# PCIe_SS1_RC_CFG_DBICS register map
Vendor: Texas Instruments
Peripheral module from a debugger description file (folder DRA75x_DRA74x).
Registers are 32-bit, access per field, reset 0x0 unless marked. A register's access mark holds for its fields unless they carry their own. Offsets are as the file gives them; lines under a group give offsets from that group; [hi:lo] are bit positions; {n}, {i} and the like mark numbered series; 'fields as' and 'values as' point back to an identical list; <NAME> marks a mode.

## PCIe_SS1_RC_CFG_DBICS
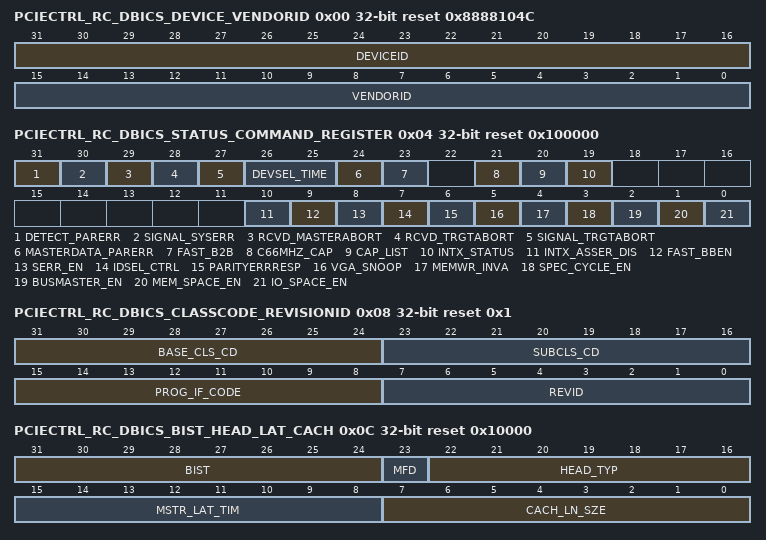
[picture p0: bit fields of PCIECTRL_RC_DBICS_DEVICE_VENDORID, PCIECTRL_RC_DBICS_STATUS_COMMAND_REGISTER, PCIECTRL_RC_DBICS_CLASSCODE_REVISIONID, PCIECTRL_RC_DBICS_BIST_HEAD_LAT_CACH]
0x00 PCIECTRL_RC_DBICS_DEVICE_VENDORID rw reset 0x8888104C — Device and Vendor ID
  [31:16] DEVICEID — Device ID (CS)
  [15:0] VENDORID — Vendor ID (CS)
0x04 PCIECTRL_RC_DBICS_STATUS_COMMAND_REGISTER reset 0x100000 — Status and Command registers
  [31] DETECT_PARERR rw — Detected Parity Error
  [30] SIGNAL_SYSERR rw — Signaled System Error
  [29] RCVD_MASTERABORT rw — Received Master Abort
  [28] RCVD_TRGTABORT rw — Received Target Abort
  [27] SIGNAL_TRGTABORT rw — Signaled Target Abort
  [26:25] DEVSEL_TIME ro — DevSel Timing, Harsdwired to 0 for PCIExpress
  [24] MASTERDATA_PARERR rw — Master Data Parity Error
  [23] FAST_B2B ro — Back to Back Capable, Harsdwired to 0 for PCIExpress
  [21] C66MHZ_CAP ro — 66MHz Capable, Harsdwired to 0 for PCIExpress
  [20] CAP_LIST ro — Capabilities List Hardwired to 1
  [19] INTX_STATUS ro
  [10] INTX_ASSER_DIS rw — INTx Assertion Disable
  [9] FAST_BBEN ro — Bit hardwired to 0 for PCIExpress
  [8] SERR_EN rw — SERR Enable
  [7] IDSEL_CTRL ro — Bit hardwired to 0 for PCIExpress
  [6] PARITYERRRESP rw — Parity Error Response
  [5] VGA_SNOOP ro — Not Applicable forPCI Express; Bit hardwired to 0 for PCIExpress
  [4] MEMWR_INVA ro — Not Applicable for PCI Express; Bit hardwired to 0 for PCIExpress
  [3] SPEC_CYCLE_EN ro — Not Applicable for PCI Express; Bit hardwired to 0 for PCIExpress
  [2] BUSMASTER_EN rw — Bus Master Enable (BME)
  [1] MEM_SPACE_EN rw — Memory Space Enable (MSE)
  [0] IO_SPACE_EN rw — IO Space Enable (ISE)
0x08 PCIECTRL_RC_DBICS_CLASSCODE_REVISIONID rw reset 0x1 — Class code and Revision ID
  [31:24] BASE_CLS_CD — Base Class Code (CS)
  [23:16] SUBCLS_CD — Sub Class Code (CS)
  [15:8] PROG_IF_CODE — Programming Interface Code (CS)
  [7:0] REVID — Revision ID (CS)
0x0C PCIECTRL_RC_DBICS_BIST_HEAD_LAT_CACH reset 0x10000 — BIST, Header Type, Latency Timer, Cache Line Size
  [31:24] BIST ro
  [23] MFD ro — MultiFunction Device
  [22:16] HEAD_TYP ro — Header Type
    0=TYPE0 (EP header (Type0)); 1=TYPE1 (RC header (Type1))
  [15:8] MSTR_LAT_TIM ro — Master Latency Timer, Not Applicable for PCIe hence hardwired to 0
  [7:0] CACH_LN_SZE rw — Cache Line Size, No impact on write, write is allowed only for legacy purpose
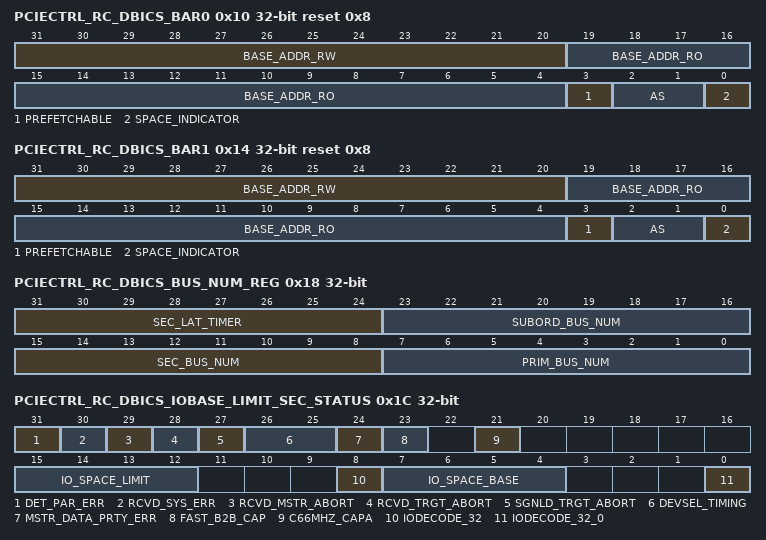
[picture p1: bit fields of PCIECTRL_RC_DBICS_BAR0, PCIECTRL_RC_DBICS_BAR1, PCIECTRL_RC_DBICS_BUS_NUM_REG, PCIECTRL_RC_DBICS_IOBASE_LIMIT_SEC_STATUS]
0x10 PCIECTRL_RC_DBICS_BAR0 reset 0x8 — Base Address Register 0 Bit #0 is also a WO BAR enable (CS2) BAR Mask is writable (CS2)
  [31:20] BASE_ADDR_RW rw — Base address bits (for a 64-bit BAR, upper base address bits are in BAR above). Unmasked MSBs, as set by BAR mask.NOTE: The RO and RW division between bits 19 and 20 is based on the assumption that BAR mask is 20 bits (1MB).
  [19:4] BASE_ADDR_RO ro — Base address bits (for a 64-bit BAR, upper base address bits are in BAR above). Masked LSBs, as set by BAR mask.NOTE: The RO and RW division between bits 19 and 20 is based on the assumption that BAR mask is 20 bits (1MB).
  [3] PREFETCHABLE rw — MEM BAR: Prefetchable (CS) I/O BAR: bit 1 is part of I/O address
  [2:1] AS rw — MEM BAR: Address Size (CS) I/O BAR: bit 0 is always 0, bit 1 is LS Bit of I/O addressRead 0x0 = 32 bit enum=_32BIT . Read 0x2 = 64 bit enum=_64BIT .
  [0] SPACE_INDICATOR rw — BAR I/O vs memory space indicator (CS)
    0=MEM (BAR type is Memory (MEM)); 1=IO (BAR type is I/O (IO))
0x14 PCIECTRL_RC_DBICS_BAR1 reset 0x8 — Base Address Register 1 If BAR0.AS = 64-bit: upper half of BAR0 base address If BAR0.AS = 32-bit: independent 32-bit BAR Bit #0 is also a WO BAR enable (CS2) BAR Mask is writable (CS2)
  [31:20] BASE_ADDR_RW rw — Base address bits (for a 64-bit BAR, lower base address bits are in BAR below). Unmasked MSBs, as set by BAR mask.NOTE: The RO and RW division between bits 19 and 20 is based on the assumption that BAR mask is 20 bits (1MB).
  [19:4] BASE_ADDR_RO ro — Base address bits (for a 64-bit BAR, lower base address bits are in BAR below). Masked LSBs, as set by BAR mask.NOTE: The RO and RW division between bits 19 and 20 is based on the assumption that BAR mask is 20 bits (1MB).
  [3] PREFETCHABLE rw — MEM BAR: Prefetchable (CS) I/O BAR: bit 1 is part of I/O address
  [2:1] AS rw — MEM BAR: Address Size (CS) I/O BAR: bit 0 is always 0, bit 1 is LSBit of I/O addressRead 0x0 = 32 bit enum=_32BIT . Read 0x2 = 64 bit enum=_64BIT .
  [0] SPACE_INDICATOR rw — BAR I/O vs memory space indicator (CS)
    values as PCIECTRL_RC_DBICS_BAR0.SPACE_INDICATOR
0x18 PCIECTRL_RC_DBICS_BUS_NUM_REG — Bus Number Registers
  [31:24] SEC_LAT_TIMER ro — Secondary Latency Timer, Not Applicable for PCI Express hence hardwired to 0
  [23:16] SUBORD_BUS_NUM rw — Subordinate Bus Number
  [15:8] SEC_BUS_NUM rw — Secondary Bus Number
  [7:0] PRIM_BUS_NUM rw — Primary Bus Number
0x1C PCIECTRL_RC_DBICS_IOBASE_LIMIT_SEC_STATUS — IO Base,Limit and Secondary Status Register
  [31] DET_PAR_ERR rw — Detected Parity Error
  [30] RCVD_SYS_ERR rw — Received System Error
  [29] RCVD_MSTR_ABORT rw — Received Master Abort
  [28] RCVD_TRGT_ABORT rw — Received Target Error
  [27] SGNLD_TRGT_ABORT rw — Signaled Target Error
  [26:25] DEVSEL_TIMING ro — DEVSEL Timing, Not Applicable for PCI Express hence hardwired to 0
  [24] MSTR_DATA_PRTY_ERR rw — Mastered Data Parity Error
  [23] FAST_B2B_CAP ro — Fast Back to Back Capable, Not Applicable for PCI Express hence hardwired to 0
  [21] C66MHZ_CAPA ro — 66MHz Capable, Not Applicable for PCI Express hence hardwired to 0
  [15:12] IO_SPACE_LIMIT rw
  [8] IODECODE_32 ro — 32 or 16 Bit IO Space
  [7:4] IO_SPACE_BASE rw — IO_Space_Limit
  [0] IODECODE_32_0 ro — 32 or 16 Bit IO Space (CS)
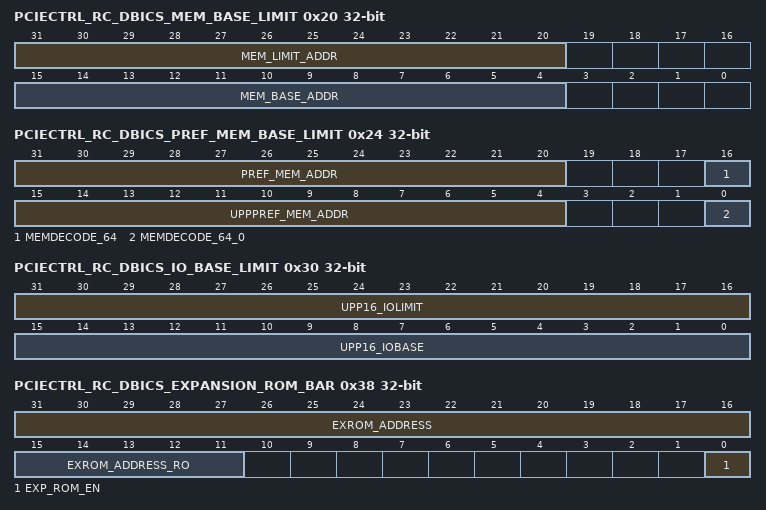
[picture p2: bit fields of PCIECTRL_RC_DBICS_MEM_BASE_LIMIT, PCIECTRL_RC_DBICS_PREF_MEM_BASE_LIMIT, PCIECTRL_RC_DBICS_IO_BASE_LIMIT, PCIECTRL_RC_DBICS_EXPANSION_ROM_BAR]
0x20 PCIECTRL_RC_DBICS_MEM_BASE_LIMIT — Memory Base and Limit Register
  [31:20] MEM_LIMIT_ADDR rw — Memory Limit Address
  [15:4] MEM_BASE_ADDR rw — Memory Base Address
0x24 PCIECTRL_RC_DBICS_PREF_MEM_BASE_LIMIT — Prefetchable Memory Base and Limit Register
  [31:20] PREF_MEM_ADDR rw — Upper 12 bits of 32-bit Prefetchable Memory End Address
  [16] MEMDECODE_64 ro — 64-Bit Memory Addressing
  [15:4] UPPPREF_MEM_ADDR rw — Upper 12 bits of 32-bit Prefetchable Memory start Address
  [0] MEMDECODE_64_0 ro — 64-Bit Memory Addressing
0x28 PCIECTRL_RC_DBICS_UPPER_32BIT_PREF_BASEADDR rw — Upper 32 Bit Prefetachable Base Address Register
  [31:0] ADDRUPP — Upper 32 Bits of Base Address of Prefetachable Memory Space, Used only if 64 Bit Prefetachable Addresing is enabled
0x2C PCIECTRL_RC_DBICS_UPPER_32BIT_PREF_LIMITADDR rw — Upper 32 Bit Prefetachable Limit Address Register
  [31:0] ADDRUPP_LIMIT — Upper 32 Bits of Limit Address of Prefetachable Memory Space, Used only if 64 Bit Prefetachable Addresing is enabled
0x30 PCIECTRL_RC_DBICS_IO_BASE_LIMIT rw — IO Base and Limit Register
  [31:16] UPP16_IOLIMIT — Upper 16 IO Limit Address
  [15:0] UPP16_IOBASE — Upper 16 IO Base Address
0x34 PCIECTRL_RC_DBICS_CAPPTR reset 0x40 — CapPtr
  [7:0] CAPTR rw — First Capability Pointer (CS)
0x38 PCIECTRL_RC_DBICS_EXPANSION_ROM_BAR — Expansion ROM Base Address Register
  [31:16] EXROM_ADDRESS rw — Expansion ROM address, unmasked (ie programmable)
  [15:11] EXROM_ADDRESS_RO ro — Expansion ROM address, masked.
  [0] EXP_ROM_EN rw — Expansion ROM Enable
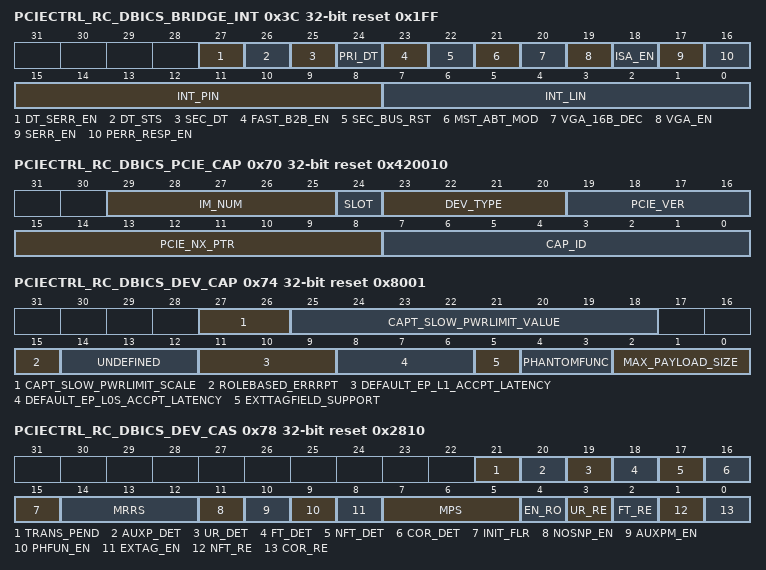
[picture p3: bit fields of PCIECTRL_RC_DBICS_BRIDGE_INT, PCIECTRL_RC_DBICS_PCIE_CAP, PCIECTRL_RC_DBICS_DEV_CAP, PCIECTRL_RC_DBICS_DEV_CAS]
0x3C PCIECTRL_RC_DBICS_BRIDGE_INT reset 0x1FF — Bridge Control and Int Pin and line
  [27] DT_SERR_EN ro — Discard Timer SERR Enable Status
  [26] DT_STS ro — Discard Timer Status
  [25] SEC_DT ro — Secondary Discard Timer
  [24] PRI_DT ro — Primary Discard Timer
  [23] FAST_B2B_EN ro — Fast Back-to-Back Transactions Enable
  [22] SEC_BUS_RST rw — Secondary Bus Reset (initiate hot reset)
  [21] MST_ABT_MOD ro — Master Abort Mode
  [20] VGA_16B_DEC rw — VGA 16-Bit Decode
  [19] VGA_EN rw — VGA Enable
  [18] ISA_EN rw — ISA Enable
  [17] SERR_EN rw — SERR Enable
  [16] PERR_RESP_EN rw — Parity Error Response Enable
  [15:8] INT_PIN ro — Interrupt Pin (CS)
  [7:0] INT_LIN rw — Interrupt Line
0x70 PCIECTRL_RC_DBICS_PCIE_CAP reset 0x420010 — PCI Express Capability structure header
  [29:25] IM_NUM rw — Interrupt Message Number (CS)
  [24] SLOT rw — Slot Implemented (CS)
  [23:20] DEV_TYPE ro — Device/Port Type
    4=RC (RC root port (RC))
  [19:16] PCIE_VER ro — PCI Express Capability Version
  [15:8] PCIE_NX_PTR rw — Next Capability Pointer (CS)
  [7:0] CAP_ID ro — Capability ID
    16=PCIE
0x74 PCIECTRL_RC_DBICS_DEV_CAP reset 0x8001 — PCIE Device Capabilities
  [27:26] CAPT_SLOW_PWRLIMIT_SCALE rw — Captured Slow Power Scale Value, for Upstream Port Only (CS)
  [25:18] CAPT_SLOW_PWRLIMIT_VALUE rw — Captured Slow Power Limit Value, for Upstream Port Only (CS)
  [15] ROLEBASED_ERRRPT rw — Role Based Error Reporting (CS)
  [14:12] UNDEFINED ro — Undefined from PCIe 1.1 onwards
  [11:9] DEFAULT_EP_L1_ACCPT_LATENCY ro — Endpoint L1 Acceptable Latency; Must be 0 for RC.
  [8:6] DEFAULT_EP_L0S_ACCPT_LATENCY ro — Endpoint L0s Acceptable Latency; Must be 0 for RC.
  [5] EXTTAGFIELD_SUPPORT rw — Extended Tag Field Support (CS)
  [4:3] PHANTOMFUNC rw — Phantom Function Support, not SUPPORTED (CS)
  [2:0] MAX_PAYLOAD_SIZE rw — Maximum Payload Size (CS)
    1=_256_BYTE
0x78 PCIECTRL_RC_DBICS_DEV_CAS reset 0x2810 — PCIE Device Control and Status
  [21] TRANS_PEND ro — Transaction Pending
  [20] AUXP_DET ro — Aux Power Detected
  [19] UR_DET rw — Unsupported Request Detected
  [18] FT_DET rw — Fatal Error Detected
  [17] NFT_DET rw — Non-Fatal Error Detected
  [16] COR_DET rw — Correctable Error Detected
  [15] INIT_FLR ro — Reserved
  [14:12] MRRS rw — Max_Read_Request_Size
  [11] NOSNP_EN rw — Enable No Snoop
  [10] AUXPM_EN rw — AUX Power PM Enable (Sticky bit)
    0=DIS (Vaux not used by device); 1=EN (Device can draw Vaux power; Sticky bits will be preserved over reset)
  [9] PHFUN_EN rw — Phantom Function Enable
  [8] EXTAG_EN rw — Extended Tag Field Enable
  [7:5] MPS rw — Max_Payload_Size
  [4] EN_RO rw — Enable Relaxed Ordering
  [3] UR_RE rw — Unsupported Request Reporting Enable
  [2] FT_RE rw — Fatal Error Reporting Enable
  [1] NFT_RE rw — Non-Fatal Error Reporting Enable
  [0] COR_RE rw — Correctable Error Reporting Enable
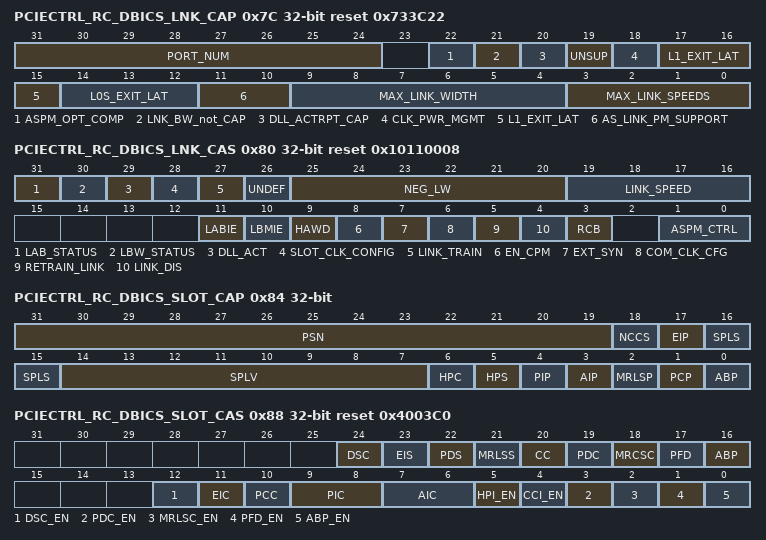
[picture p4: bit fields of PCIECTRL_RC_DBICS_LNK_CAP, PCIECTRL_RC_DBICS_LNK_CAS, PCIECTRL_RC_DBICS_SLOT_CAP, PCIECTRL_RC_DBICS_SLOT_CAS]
0x7C PCIECTRL_RC_DBICS_LNK_CAP reset 0x733C22 — PCIE Link Capabilities
  [31:24] PORT_NUM rw — Port Number (CS)
  [22] ASPM_OPT_COMP rw — ASPM Optionality Compliance (CS)
  [21] LNK_BW_not_CAP rw — Link Bandwidth Notification Capability (CS)
  [20] DLL_ACTRPT_CAP ro — Data Link Layer Active Reporting Capable
  [19] UNSUP ro — Unsupported, Surprise Down Error Reporting Capable, Hardwired to 0
  [18] CLK_PWR_MGMT rw — Clock Power Management; Hardwired to 0 for DS port (RC); (CS)
  [17:15] L1_EXIT_LAT rw — L1 Exit Latency (CS) Compare CS2
  [14:12] L0S_EXIT_LAT rw — L0s Exit Latency (CS) Compare CS2
  [11:10] AS_LINK_PM_SUPPORT rw — Active State Link PM (ASPM) Support (CS)
  [9:4] MAX_LINK_WIDTH rw — Max Link Width (lanes) (CS)
  [3:0] MAX_LINK_SPEEDS rw — Supported Max Link Speed (CS) Read 0x1: 2.5 GT/s (Gen1) Read 0x2: 5 GT/s (Gen2) Read 0x3: 8 GT/s (Gen3)
0x80 PCIECTRL_RC_DBICS_LNK_CAS access not given reset 0x10110008 — PCIE Link Control and Status
  [31] LAB_STATUS — Link Autonomous Bandwidth Status (access RW Wr1toClr)
  [30] LBW_STATUS — Link Bandwidth Management Status (access RW Wr1toClr)
  [29] DLL_ACT ro — Data Link Layer Active
  [28] SLOT_CLK_CONFIG rw — Slot Clock Configuration (CS)
  [27] LINK_TRAIN ro — LINK training
  [26] UNDEF ro — Undefined
  [25:20] NEG_LW ro — Negotiated Link Width; UNDEFINED UNTIL LINK IS UP.
  [19:16] LINK_SPEED ro — Link Speed; UNDEFINED UNTIL LINK IS UP.
  [11] LABIE rw — Link Autonomous Bandwidth Interrupt Enable
  [10] LBMIE rw — Link Bandwidth Management Interrupt Enable
  [9] HAWD ro — Hardware Autonomous Width Disable
  [8] EN_CPM rw — Enable Clock Power Management
  [7] EXT_SYN rw — Extended Synch
  [6] COM_CLK_CFG rw — Common Clock Configuration
    0=ASYNC (Asynchronous reference clocks (ASYNC)); 1=COMMON (Distributed common reference clock (COMMON))
  [5] RETRAIN_LINK rw
  [4] LINK_DIS rw — Link Disable
  [3] RCB rw — Read Completion Boundary (CS)
    0=_64_BYTE; 1=_128_BYTE
  [1:0] ASPM_CTRL rw — Active State Link PM Control 0x0: DISABLED 0x1: L0S_ENABLED 0x2: L1_ENABLED 0x3: L0S_AND_L1_ENABLED
0x84 PCIECTRL_RC_DBICS_SLOT_CAP rw — Slot Capabilities Register
  [31:19] PSN — Physical Slot Number (CS)
  [18] NCCS — No Command Complete Support (CS)
  [17] EIP — Electromechanical Interlock Present (CS)
  [16:15] SPLS — Slot Power Limit Scale (CS)
  [14:7] SPLV — Slot Power Limit Value (CS)
  [6] HPC — Hot-Plug Capable (CS)
  [5] HPS — Hot-Plug Surprise (CS)
  [4] PIP — Power Indicator Present (CS)
  [3] AIP — Attention Indicator Present (CS)
  [2] MRLSP — MRL Sensor Present (CS)
  [1] PCP — Power Controller Present (CS)
  [0] ABP — Attention Button Present (CS)
0x88 PCIECTRL_RC_DBICS_SLOT_CAS reset 0x4003C0 — Slot Control and Status Register
  [24] DSC rw — Data Link Layer State Changed
  [23] EIS ro — Electromechanical Interlock Status
  [22] PDS ro — Presence Detect State NO PRESENCE DETECTION IMPLEMENTED: TIED TO 1
  [21] MRLSS ro — MRL Sensor State
  [20] CC rw — Command Completed
  [19] PDC rw — Presence Detect Changed
  [18] MRCSC rw — MRL Sensor Changed
  [17] PFD rw — Power Fault Detected
  [16] ABP rw — Attention Button Pressed
  [12] DSC_EN rw — Data Link Layer State Changed Enable
  [11] EIC rw — Electromechanical Interlock Control
  [10] PCC rw — Power Controller Control
  [9:8] PIC rw — Power Indicator Control
  [7:6] AIC rw — Attention Indicator Control
  [5] HPI_EN rw — Hot-Plug Interrupt Enable
  [4] CCI_EN rw — Command Completed Interrupt Enable
  [3] PDC_EN rw — Presence Detect Changed Enable
  [2] MRLSC_EN rw — MRL Sensor Changed Enable
  [1] PFD_EN rw — Power Fault Detected Enable
  [0] ABP_EN rw — Attention Button Pressed Enable
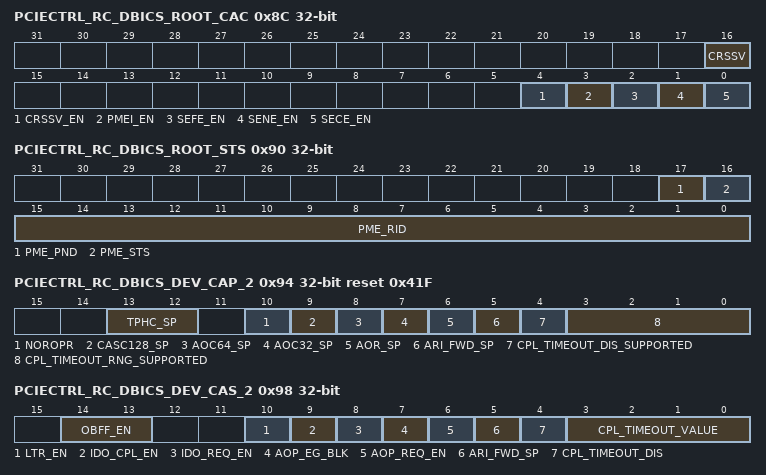
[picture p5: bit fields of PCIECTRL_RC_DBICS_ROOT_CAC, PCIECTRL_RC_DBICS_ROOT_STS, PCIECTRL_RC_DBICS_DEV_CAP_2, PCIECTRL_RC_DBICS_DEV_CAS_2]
0x8C PCIECTRL_RC_DBICS_ROOT_CAC — Root Control and Capability Register
  [16] CRSSV ro — CRS Software Visibility
  [4] CRSSV_EN ro — CRS Software Visibility Enable
  [3] PMEI_EN rw — PME Interrupt Enable
  [2] SEFE_EN rw — System Error on Fatal Error Enable
  [1] SENE_EN rw — System Error on Non-fatal Error Enable
  [0] SECE_EN rw — System Error on Correctable Error Enable
0x90 PCIECTRL_RC_DBICS_ROOT_STS — Root Status Register
  [17] PME_PND ro — PME Pending
  [16] PME_STS rw — PME Status (Sticky bit)
  [15:0] PME_RID ro — PME Requester ID
0x94 PCIECTRL_RC_DBICS_DEV_CAP_2 ro reset 0x41F — Device Capabilities 2 Register
  [13:12] TPHC_SP — TPH Completer Supported
  [10] NOROPR — No RO-enabled PR-PR Passing
  [9] CASC128_SP — 128-bit CAS Completer Supported
  [8] AOC64_SP — 64-bit AtomicOp Completer Supported
  [7] AOC32_SP — 32-bit AtomicOp Completer Supported
  [6] AOR_SP — AtomicOp Routing Supported
  [5] ARI_FWD_SP — ARI Forwarding Supported
  [4] CPL_TIMEOUT_DIS_SUPPORTED — Completion Timeout Disable Supported
  [3:0] CPL_TIMEOUT_RNG_SUPPORTED — Completion Timeout Ranges Supported
0x98 PCIECTRL_RC_DBICS_DEV_CAS_2 — Device Control 2 Register
  [14:13] OBFF_EN rw — OBFF Enable
  [10] LTR_EN rw — LTR Mechanism Enable
  [9] IDO_CPL_EN rw — IDO Completion Enable
  [8] IDO_REQ_EN rw — IDO Request Enable
  [7] AOP_EG_BLK rw — AtomicOp Egress Blocking
  [6] AOP_REQ_EN rw — AtomicOp Requester Enable
  [5] ARI_FWD_SP rw — ARI Forwarding Supported
  [4] CPL_TIMEOUT_DIS rw — Completion Timeout Disable
  [3:0] CPL_TIMEOUT_VALUE rw — Completion Timeout Values
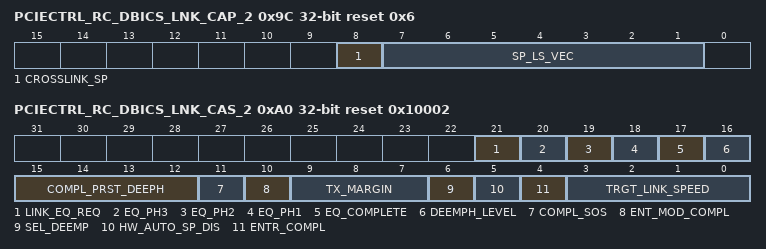
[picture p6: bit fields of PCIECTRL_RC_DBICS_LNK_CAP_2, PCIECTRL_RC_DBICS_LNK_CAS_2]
0x9C PCIECTRL_RC_DBICS_LNK_CAP_2 ro reset 0x6 — PCIE Link Capabilities 2 Register
  [8] CROSSLINK_SP — Crosslink Supported
  [7:1] SP_LS_VEC — Supported Link Speeds Vector
0xA0 PCIECTRL_RC_DBICS_LNK_CAS_2 access not given reset 0x10002 — Link Control and Status 2 Register (Sticky)
  [21] LINK_EQ_REQ — Link Equilization Request (access RW Wr1toClr)
  [20] EQ_PH3 ro — Equalization Ph3 Success, Gen3 Only
  [19] EQ_PH2 ro — Equalization Ph2 Success, Gen3 Only
  [18] EQ_PH1 ro — Equalization Ph1 Success, Gen3 Only
  [17] EQ_COMPLETE ro — Equalization Complete, Gen3 Only
  [16] DEEMPH_LEVEL ro — Current De-emphasis Level
  [15:12] COMPL_PRST_DEEPH rw — Compliance Pre-set/ De-emphasis
  [11] COMPL_SOS rw — Compliance SOS
  [10] ENT_MOD_COMPL rw — Enter Modified Compliance
  [9:7] TX_MARGIN rw — Transmit Margin
  [6] SEL_DEEMP rw — Selectable De-emphasis (CS)
  [5] HW_AUTO_SP_DIS rw — Hardware Autonomous Speed Disable
  [4] ENTR_COMPL rw — Enter Compliance
  [3:0] TRGT_LINK_SPEED rw — Target Link Speed Read 0x1: 2.5 GT/s (Gen1) Read 0x2: 5 GT/s (Gen2) Read 0x3: 8 GT/s (Gen3)
